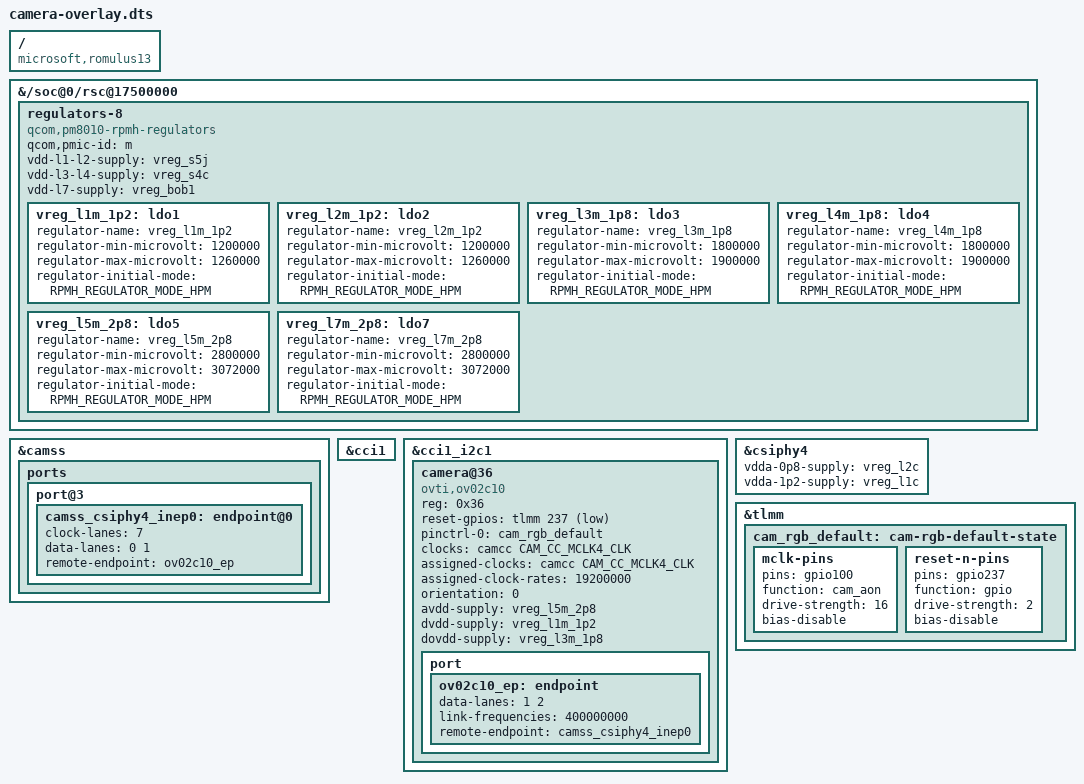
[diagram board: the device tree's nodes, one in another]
/dts-v1/;
/plugin/;
#include <dt-bindings/gpio/gpio.h>
#include <dt-bindings/regulator/qcom,rpmh-regulator.h>
#include <dt-bindings/clock/qcom,x1e80100-camcc.h>
/ { compatible = "microsoft,romulus13", "qcom,x1e80100"; };
&{/soc@0/rsc@17500000} {

	regulators-8 {
		compatible = "qcom,pm8010-rpmh-regulators";
		qcom,pmic-id = "m";

		vdd-l1-l2-supply = <&vreg_s5j>;
		vdd-l3-l4-supply = <&vreg_s4c>;
		vdd-l7-supply = <&vreg_bob1>;

		vreg_l1m_1p2: ldo1 {
			regulator-name = "vreg_l1m_1p2";
			regulator-min-microvolt = <1200000>;
			regulator-max-microvolt = <1260000>;
			regulator-initial-mode = <RPMH_REGULATOR_MODE_HPM>;
		};

		vreg_l2m_1p2: ldo2 {
			regulator-name = "vreg_l2m_1p2";
			regulator-min-microvolt = <1200000>;
			regulator-max-microvolt = <1260000>;
			regulator-initial-mode = <RPMH_REGULATOR_MODE_HPM>;
		};

		vreg_l3m_1p8: ldo3 {
			regulator-name = "vreg_l3m_1p8";
			regulator-min-microvolt = <1800000>;
			regulator-max-microvolt = <1900000>;
			regulator-initial-mode = <RPMH_REGULATOR_MODE_HPM>;
		};

		vreg_l4m_1p8: ldo4 {
			regulator-name = "vreg_l4m_1p8";
			regulator-min-microvolt = <1800000>;
			regulator-max-microvolt = <1900000>;
			regulator-initial-mode = <RPMH_REGULATOR_MODE_HPM>;
		};

		vreg_l5m_2p8: ldo5 {
			regulator-name = "vreg_l5m_2p8";
			regulator-min-microvolt = <2800000>;
			regulator-max-microvolt = <3072000>;
			regulator-initial-mode = <RPMH_REGULATOR_MODE_HPM>;
		};

		vreg_l7m_2p8: ldo7 {
			regulator-name = "vreg_l7m_2p8";
			regulator-min-microvolt = <2800000>;
			regulator-max-microvolt = <3072000>;
			regulator-initial-mode = <RPMH_REGULATOR_MODE_HPM>;
		};
	};
};
&camss {
	status = "okay";

	ports {
		/*
		 * port0 => csiphy0
		 * port1 => csiphy1
		 * port2 => csiphy2
		 * port3 => csiphy4
		 */
		port@3 {
			camss_csiphy4_inep0: endpoint@0 {
				clock-lanes = <7>;
				data-lanes = <0 1>;
				remote-endpoint = <&ov02c10_ep>;
			};
		};
	};
};

&cci1 {
	status = "okay";
};

&cci1_i2c1 {
	camera@36 {
		compatible = "ovti,ov02c10";
		reg = <0x36>;

		reset-gpios = <&tlmm 237 GPIO_ACTIVE_LOW>;
		pinctrl-names = "default";
		pinctrl-0 = <&cam_rgb_default>;

		clocks = <&camcc CAM_CC_MCLK4_CLK>;
		assigned-clocks = <&camcc CAM_CC_MCLK4_CLK>;
		assigned-clock-rates = <19200000>;

		orientation = <0>; /* front facing */

		avdd-supply = <&vreg_l5m_2p8>;
		dvdd-supply = <&vreg_l1m_1p2>;
		dovdd-supply = <&vreg_l3m_1p8>;

		port {
			ov02c10_ep: endpoint {
				data-lanes = <1 2>;
				link-frequencies = /bits/ 64 <400000000>;
				remote-endpoint = <&camss_csiphy4_inep0>;
			};
		};
	};
};

&csiphy4 {
	vdda-0p8-supply = <&vreg_l2c>;
	vdda-1p2-supply = <&vreg_l1c>;

	status = "okay";
};

&tlmm {
	cam_rgb_default: cam-rgb-default-state {
		mclk-pins {
			pins = "gpio100";
			function = "cam_aon";
			drive-strength = <16>;
			bias-disable;
		};

		reset-n-pins {
			pins = "gpio237";
			function = "gpio";
			drive-strength = <2>;
			bias-disable;
		};
	};

};
